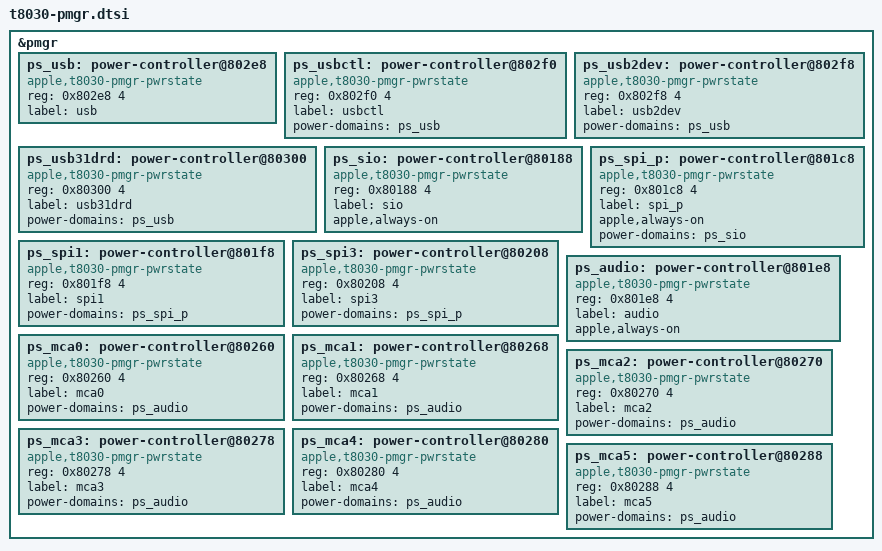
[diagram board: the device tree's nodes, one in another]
// SPDX-License-Identifier: GPL-2.0-only OR MIT
/*
 * Apple T8030 USB power domains
 *
 * Copyright (c) 2026, Yuriy Havrylyuk <yhavry@gmail.com>
 */

&pmgr {
	ps_usb: power-controller@802e8 {
		compatible = "apple,t8030-pmgr-pwrstate",
			     "apple,t8103-pmgr-pwrstate";
		reg = <0x802e8 4>;
		#power-domain-cells = <0>;
		#reset-cells = <0>;
		label = "usb";
	};

	ps_usbctl: power-controller@802f0 {
		compatible = "apple,t8030-pmgr-pwrstate",
			     "apple,t8103-pmgr-pwrstate";
		reg = <0x802f0 4>;
		#power-domain-cells = <0>;
		#reset-cells = <0>;
		label = "usbctl";
		power-domains = <&ps_usb>;
	};

	ps_usb2dev: power-controller@802f8 {
		compatible = "apple,t8030-pmgr-pwrstate",
			     "apple,t8103-pmgr-pwrstate";
		reg = <0x802f8 4>;
		#power-domain-cells = <0>;
		#reset-cells = <0>;
		label = "usb2dev";
		power-domains = <&ps_usb>;
	};

	ps_usb31drd: power-controller@80300 {
		compatible = "apple,t8030-pmgr-pwrstate",
			     "apple,t8103-pmgr-pwrstate";
		reg = <0x80300 4>;
		#power-domain-cells = <0>;
		#reset-cells = <0>;
		label = "usb31drd";
		power-domains = <&ps_usb>;
	};
};

/* SIO/SPI_P/SPI1 from the ADT pmgr device list: psreg 2 base 0x80100, psidx 17/25/31 */
&pmgr {
	ps_sio: power-controller@80188 {
		compatible = "apple,t8030-pmgr-pwrstate",
			     "apple,t8103-pmgr-pwrstate";
		reg = <0x80188 4>;
		#power-domain-cells = <0>;
		#reset-cells = <0>;
		label = "sio";
		apple,always-on;
	};

	ps_spi_p: power-controller@801c8 {
		compatible = "apple,t8030-pmgr-pwrstate",
			     "apple,t8103-pmgr-pwrstate";
		reg = <0x801c8 4>;
		#power-domain-cells = <0>;
		#reset-cells = <0>;
		label = "spi_p";
		apple,always-on;
		power-domains = <&ps_sio>;
	};

	ps_spi1: power-controller@801f8 {
		compatible = "apple,t8030-pmgr-pwrstate",
			     "apple,t8103-pmgr-pwrstate";
		reg = <0x801f8 4>;
		#power-domain-cells = <0>;
		#reset-cells = <0>;
		label = "spi1";
		power-domains = <&ps_spi_p>;
	};

	ps_spi3: power-controller@80208 {
		compatible = "apple,t8030-pmgr-pwrstate",
			     "apple,t8103-pmgr-pwrstate";
		reg = <0x80208 4>;
		#power-domain-cells = <0>;
		#reset-cells = <0>;
		label = "spi3";
		power-domains = <&ps_spi_p>;
	};
};

/* AUDIO/MCA0-5 from the ADT pmgr device list: psreg 3 base 0x80200, psidx 12-17; AUDIO is gate 87 */
&pmgr {
	ps_audio: power-controller@801e8 {
		compatible = "apple,t8030-pmgr-pwrstate",
			     "apple,t8103-pmgr-pwrstate";
		reg = <0x801e8 4>;
		#power-domain-cells = <0>;
		#reset-cells = <0>;
		label = "audio";
		apple,always-on;
	};

	ps_mca0: power-controller@80260 {
		compatible = "apple,t8030-pmgr-pwrstate",
			     "apple,t8103-pmgr-pwrstate";
		reg = <0x80260 4>;
		#power-domain-cells = <0>;
		#reset-cells = <0>;
		label = "mca0";
		power-domains = <&ps_audio>;
	};

	ps_mca1: power-controller@80268 {
		compatible = "apple,t8030-pmgr-pwrstate",
			     "apple,t8103-pmgr-pwrstate";
		reg = <0x80268 4>;
		#power-domain-cells = <0>;
		#reset-cells = <0>;
		label = "mca1";
		power-domains = <&ps_audio>;
	};

	ps_mca2: power-controller@80270 {
		compatible = "apple,t8030-pmgr-pwrstate",
			     "apple,t8103-pmgr-pwrstate";
		reg = <0x80270 4>;
		#power-domain-cells = <0>;
		#reset-cells = <0>;
		label = "mca2";
		power-domains = <&ps_audio>;
	};

	ps_mca3: power-controller@80278 {
		compatible = "apple,t8030-pmgr-pwrstate",
			     "apple,t8103-pmgr-pwrstate";
		reg = <0x80278 4>;
		#power-domain-cells = <0>;
		#reset-cells = <0>;
		label = "mca3";
		power-domains = <&ps_audio>;
	};

	ps_mca4: power-controller@80280 {
		compatible = "apple,t8030-pmgr-pwrstate",
			     "apple,t8103-pmgr-pwrstate";
		reg = <0x80280 4>;
		#power-domain-cells = <0>;
		#reset-cells = <0>;
		label = "mca4";
		power-domains = <&ps_audio>;
	};

	ps_mca5: power-controller@80288 {
		compatible = "apple,t8030-pmgr-pwrstate",
			     "apple,t8103-pmgr-pwrstate";
		reg = <0x80288 4>;
		#power-domain-cells = <0>;
		#reset-cells = <0>;
		label = "mca5";
		power-domains = <&ps_audio>;
	};
};
